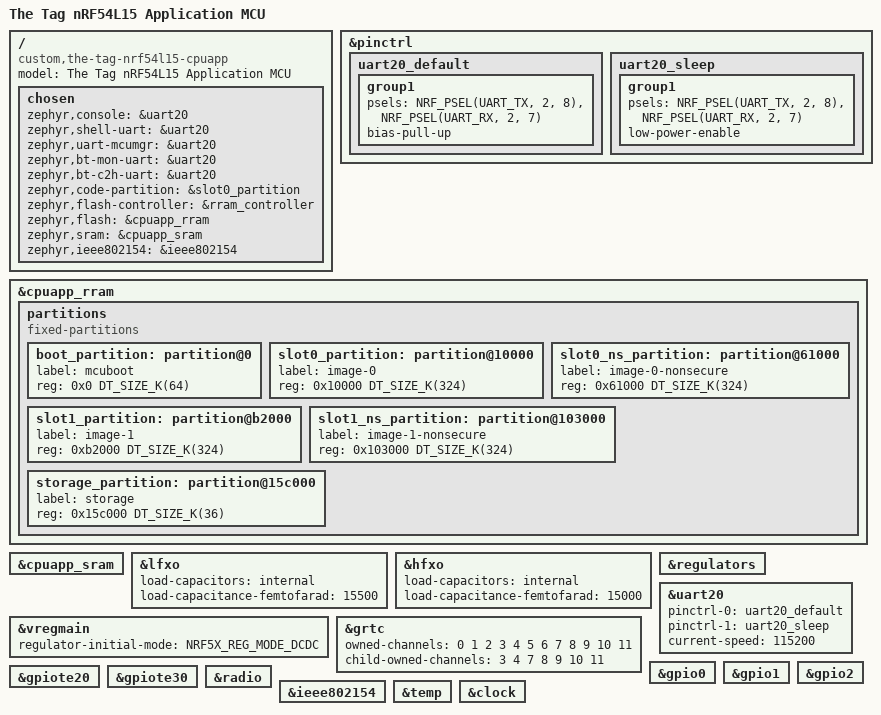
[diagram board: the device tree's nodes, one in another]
/*
 * SPDX-License-Identifier: Apache-2.0
 */

/dts-v1/;
#include <nordic/nrf54l15_cpuapp.dtsi>

/ {
	model = "The Tag nRF54L15 Application MCU";
	compatible = "custom,the-tag-nrf54l15-cpuapp";

	chosen {
		zephyr,console = &uart20;
		zephyr,shell-uart = &uart20;
		zephyr,uart-mcumgr = &uart20;
		zephyr,bt-mon-uart = &uart20;
		zephyr,bt-c2h-uart = &uart20;
		zephyr,code-partition = &slot0_partition;
		zephyr,flash-controller = &rram_controller;
		zephyr,flash = &cpuapp_rram;
		zephyr,sram = &cpuapp_sram;
		zephyr,ieee802154 = &ieee802154;
	};
};

&pinctrl {
	/omit-if-no-ref/ uart20_default: uart20_default {
		group1 {
			psels = <NRF_PSEL(UART_TX, 2, 8)>,
				<NRF_PSEL(UART_RX, 2, 7)>;
			bias-pull-up;
		};
	};

	/omit-if-no-ref/ uart20_sleep: uart20_sleep {
		group1 {
			psels = <NRF_PSEL(UART_TX, 2, 8)>,
				<NRF_PSEL(UART_RX, 2, 7)>;
			low-power-enable;
		};
	};
};

&cpuapp_rram {
	partitions {
		compatible = "fixed-partitions";
		#address-cells = <1>;
		#size-cells = <1>;

		boot_partition: partition@0 {
			label = "mcuboot";
			reg = <0x0 DT_SIZE_K(64)>;
		};

		slot0_partition: partition@10000 {
			label = "image-0";
			reg = <0x10000 DT_SIZE_K(324)>;
		};

		slot0_ns_partition: partition@61000 {
			label = "image-0-nonsecure";
			reg = <0x61000 DT_SIZE_K(324)>;
		};

		slot1_partition: partition@b2000 {
			label = "image-1";
			reg = <0xb2000 DT_SIZE_K(324)>;
		};

		slot1_ns_partition: partition@103000 {
			label = "image-1-nonsecure";
			reg = <0x103000 DT_SIZE_K(324)>;
		};

		/* 32k from 0x154000 to 0x15bfff reserved for TF-M partitions */
		storage_partition: partition@15c000 {
			label = "storage";
			reg = <0x15c000 DT_SIZE_K(36)>;
		};
	};
};

&cpuapp_sram {
	status = "okay";
};

&lfxo {
	load-capacitors = "internal";
	load-capacitance-femtofarad = <15500>;
};

&hfxo {
	load-capacitors = "internal";
	load-capacitance-femtofarad = <15000>;
};

&regulators {
	status = "okay";
};

&vregmain {
	status = "okay";
	regulator-initial-mode = <NRF5X_REG_MODE_DCDC>;
};

&grtc {
	owned-channels = <0 1 2 3 4 5 6 7 8 9 10 11>;
	child-owned-channels = <3 4 7 8 9 10 11>;
	status = "okay";
};

&uart20 {
	status = "okay";
	pinctrl-0 = <&uart20_default>;
	pinctrl-1 = <&uart20_sleep>;
	pinctrl-names = "default", "sleep";
	current-speed = <115200>;
};

&gpio0 {
	status = "okay";
};

&gpio1 {
	status = "okay";
};

&gpio2 {
	status = "okay";
};

&gpiote20 {
	status = "okay";
};

&gpiote30 {
	status = "okay";
};

&radio {
	status = "okay";
};

&ieee802154 {
	status = "okay";
};

&temp {
	status = "okay";
};

&clock {
	status = "okay";
};
